VERSION ""

NS_ :

BS_:

BU_: BMS Third_Party_Device

BO_ 3221225472 VECTOR__INDEPENDENT_SIG_MSG: 0 Vector__XXX
 SG_ Blank : 23|8@0+ (1,0) [0|0] ""  Third_Party_Device
 SG_ Blank : 31|8@0+ (1,0) [0|0] ""  Third_Party_Device
 SG_ Blank : 39|8@0+ (1,0) [0|0] ""  Third_Party_Device
 SG_ Blank : 47|8@0+ (1,0) [0|0] ""  Third_Party_Device
 SG_ Blank : 55|8@0+ (1,0) [0|0] ""  Third_Party_Device

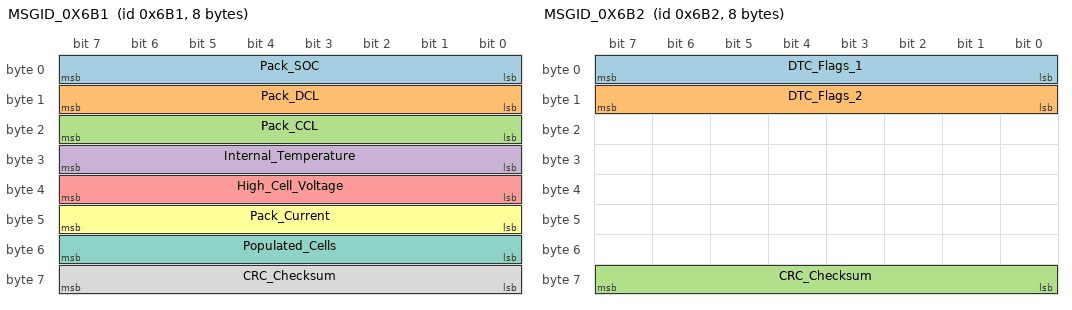
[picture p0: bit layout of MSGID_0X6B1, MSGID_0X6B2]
BO_ 1713 MSGID_0X6B1: 8 BMS
 SG_ Pack_SOC : 7|8@0+ (0.5,0) [0|0] "Percent"  Third_Party_Device
 SG_ Pack_DCL : 15|8@0+ (1,0) [0|0] "Amps"  Third_Party_Device
 SG_ Pack_CCL : 23|8@0+ (1,0) [0|0] "Amps"  Third_Party_Device
 SG_ Internal_Temperature : 31|8@0+ (1,0) [0|0] "Celsius"  Third_Party_Device
 SG_ High_Cell_Voltage : 39|8@0+ (0.0001,0) [0|0] "Volts"  Third_Party_Device
 SG_ Pack_Current : 47|8@0+ (0.1,0) [0|0] "Amps"  Third_Party_Device
 SG_ Populated_Cells : 55|8@0+ (1,0) [0|0] "Num"  Third_Party_Device
 SG_ CRC_Checksum : 63|8@0+ (1,0) [0|0] ""  Third_Party_Device

BO_ 1714 MSGID_0X6B2: 8 BMS
 SG_ DTC_Flags_1 : 7|8@0+ (1,0) [0|0] ""  Third_Party_Device
 SG_ DTC_Flags_2 : 15|8@0+ (1,0) [0|0] ""  Third_Party_Device
 SG_ CRC_Checksum : 63|8@0+ (1,0) [0|0] ""  Third_Party_Device

CM_ BO_ 1713 "This ID Transmits at 8 ms.";
CM_ BO_ 1714 "This ID Transmits at 8 ms.";
